# COMPUTE_CLUSTER0_DMSC_BOOT register map
Vendor: Texas Instruments
Peripheral module from a debugger description file (folder J7VCL).
Registers are 32-bit, access per field, reset 0x0 unless marked. A register's access mark holds for its fields unless they carry their own. Offsets are as the file gives them; lines under a group give offsets from that group; [hi:lo] are bit positions; {n}, {i} and the like mark numbered series; 'fields as' and 'values as' point back to an identical list; <NAME> marks a mode.

## COMPUTE_CLUSTER0_DMSC_BOOT
0x00 CC_REVISION ro reset 0x60000000 — Compute Cluster Revision Register
  [31:0] REV — TI internal data.
0x04 CC_MSMC_DEF ro — MSMC Definition Register
  [7:0] NUM_COREPAC — Denotes the number of corepacs connected to compute cluster.0h - Two corepacs
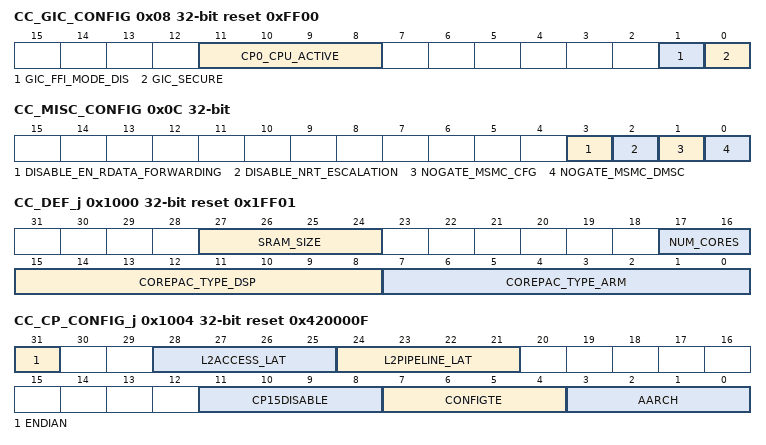
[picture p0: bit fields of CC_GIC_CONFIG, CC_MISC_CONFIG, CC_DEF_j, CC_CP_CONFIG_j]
0x08 CC_GIC_CONFIG reset 0xFF00 — GIC Configuration Register. GIC0 has input signals cpu_active_X_N (where X = A72SS number; N = Core number) which indicate when a core is active and available for routing SPIs unlike being in a software-transparent low-power mode in which case SPIs are not routed to, and a core wake-up would result in increased power consumption.
  [11:8] CP0_CPU_ACTIVE rw — A72SS0 Cores activeBits [11-10]: ReservedBit [9]:0h - A72SS0 Core 1 is in software-transparent low-power mode such as retention1h - A72SS0 Core 1 is active and available for shared SPIsBit [8]:0h - A72SS0 Core 0 is in software-transparent low-power mode such as retention1h - A72SS0 Core 0 is active and available for shared SPIs
  [1] GIC_FFI_MODE_DIS rw — Disables AXI auto responses to ARM in FFI mode.
  [0] GIC_SECURE rw — Not used on this SoC
0x0C CC_MISC_CONFIG — MISC Configuration Register.
  [3] DISABLE_EN_RDATA_FORWARDING rw — Disable control for AXI2VBUSMC return data forwarding feature
  [2] DISABLE_NRT_ESCALATION rw — Disable control for MSMC NRT escalation feature
  [1] NOGATE_MSMC_CFG rw — No gate control for the Configuration Interconnect (see
  [0] NOGATE_MSMC_DMSC rw — No gate control for the DMSC Interconnect (see
0x1000 CC_DEF_j ro reset 0x1FF01 — Compute Cluster Definition Register for MSMC port j Offset = 1000h*(j + 1); where j = 0h
  [27:24] SRAM_SIZE — SRAM size (if present in the corepac)0h - 0 bytes
  [17:16] NUM_CORES — Number of cores in the corepac0h - One core1h - Two cores2h - Four cores3h - Reserved
  [15:8] COREPAC_TYPE_DSP — Not used on this SoC
  [7:0] COREPAC_TYPE_ARM — MSMC port 'j' configuration0h - A53 corepac connected to MSMC port 'j'1h - A72 corepac connected to MSMC port 'j'2h to FEh - ReservedFFh - Port not used for ARM
0x1004 CC_CP_CONFIG_j reset 0x420000F — Compute Cluster Configuration Register for MSMC port j Offset = 1004h*(j + 1); where j = 0h
  [31] ENDIAN rw — Not used on this SoC
  [28:25] L2ACCESS_LAT rw — Not used on this SoC
  [24:21] L2PIPELINE_LAT rw — Not used on this SoC
  [11:8] CP15DISABLE rw — Disable write access to some secure CP15 registers. Valid only for Arm corepacs.
  [7:4] CONFIGTE rw — Enable T32 exceptions. It sets the initial value of the TE bit in the CP15 SCTLR register. This pin is sampled only during reset of the processor. Valid only for Arm corepacs.Bits [7-6]: ReservedBit [5]:0h - TE bit is LOW for core 1 of A72SS01h - TE bit is HIGH for core 1 of A72SS0Bit [4]:0h - TE bit is LOW for core 0 of A72SS01h - TE bit is HIGH for core 0 of A72SS0
  [3:0] AARCH rw — Arm Architecture. Valid only for Arm corepacs.Bits [3-2]: ReservedBit [1]:0h - AArch32 for core 1 of A72SS01h - AArch64 for core 1 of A72SS0Bit [0]:0h - AArch32 for core 0 of A72SS01h - AArch64 for core 0 of A72SS0
0x1008 CC_RST_VEC_LO_CP0_j rw — Core 0 Boot Vector Register (Low) for MSMC port j Offset = 1008h*(j + 1); where j = 0h
  [31:0] RESET_BASE_VECTOR_LO — Low reset base vector (bits [33-2]) for Core 0 of a corepac connected to MSMC port j.
0x100C CC_RST_VEC_HI_CP0_j — Core 0 Boot Vector Register (High) for MSMC port j Offset = 100Ch*(j + 1); where j = 0h
  [16:0] RESET_BASE_VECTOR_HI rw — High reset base vector (bits [39-34]) for Core 0 of a corepac connected to MSMC port j.
0x1010 CC_RST_VEC_LO_CP1_j rw — Core 1 Boot Vector Register (Low) for MSMC port j. Offset = 1010h*(j + 1); where j = 0h
  [31:0] RESET_BASE_VECTOR_LO — Low reset base vector (bits [33-2]) for Core 1 of a corepac connected to MSMC port j.
0x1014 CC_RST_VEC_HI_CP1_j — Core 1 Boot Vector Register (High) for MSMC port j. Offset = 1014h*(j + 1); where j = 0h
  [16:0] RESET_BASE_VECTOR_HI rw — High reset base vector (bits [39-34]) for Core 1 of a corepac connected to MSMC port j.
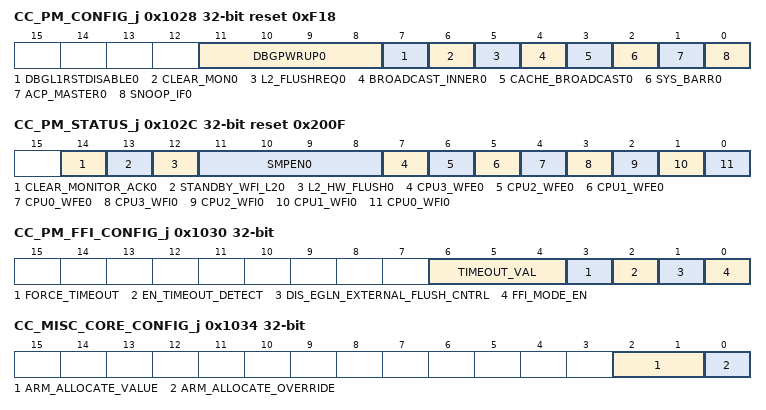
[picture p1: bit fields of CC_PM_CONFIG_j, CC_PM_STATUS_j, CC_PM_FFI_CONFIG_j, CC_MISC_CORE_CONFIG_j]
0x1028 CC_PM_CONFIG_j reset 0xF18 — Power Management Configuration Register for MSMC port j. Offset = 1028h*(j + 1); where j = 0h
  [11:8] DBGPWRUP0 rw — Core power upBits [11-10]: ReservedBit [9]:0h - A72SSj Core 1 is powered down1h - A72SSj Core 1 is powered upBit [8]:0h - A72SSj Core 0 is powered down1h - A72SSj Core 0 is powered up
  [7] DBGL1RSTDISABLE0 rw — Disable L1 data cache automatic invalidate on reset. This pin is sampled only during reset of the processor.0h - Enable automatic invalidation of L1 data cache on reset1h - Disable automatic invalidation of L1 data cache on reset
  [6] CLEAR_MON0 rw — Request to clear the external global exclusive monitor. This sends a WFE wake-up event to all cores in the cluster. When set HIGH the global exclusive monitor in the system is requesting the processor EVENT registers to be set HIGH.
  [5] L2_FLUSHREQ0 rw — ARM L2 hardware flush request
  [4] BROADCAST_INNER0 rw — Enable broadcasting of inner shareable and outer sharable transactions0h - Broadcasting disabled1h - Broadcasting enabled
  [3] CACHE_BROADCAST0 rw — Enable Broadcasting of cache maintenance transactions0h - Broadcasting disabled1h - Broadcasting enabled
  [2] SYS_BARR0 rw — Disable broadcasting of barriers0h - Broadcasting enabled1h - Broadcasting disabled
  [1] ACP_MASTER0 rw — ACP master is inactive and is not participating in coherency0h - ACP Master is active1h - ACP Master is inactiveNOTE: There must be no outstanding transactions when the master asserts this signal, and while it is asserted the master must not send any new transactions
  [0] SNOOP_IF0 rw — Snoop interface is inactive and not participating in coherency0h - Snoop interface is active1h - Snoop interface is inactive
0x102C CC_PM_STATUS_j ro reset 0x200F — Power Management Status Register for MSMC port j. Offset = 102Ch*(j + 1); where j = 0h
  [14] CLEAR_MONITOR_ACK0 — Clearing of the external global exclusive monitor acknowledge. When set HIGH the processor EVENT registers have been set HIGH.
  [13] STANDBY_WFI_L20 — L2 in WFI low power state indication
  [12] L2_HW_FLUSH0 — L2 hardware flush complete
  [11:8] SMPEN0 — Corepac taking part in coherency indication
  [7] CPU3_WFE0 — Reserved
  [6] CPU2_WFE0 — Reserved
  [5] CPU1_WFE0 — CPU in WFE state
  [4] CPU0_WFE0 — CPU in WFE state
  [3] CPU3_WFI0 — Reserved
  [2] CPU2_WFI0 — Reserved
  [1] CPU1_WFI0 — CPU in WFI state
  [0] CPU0_WFI0 — CPU in WFI state
0x1030 CC_PM_FFI_CONFIG_j — Power Management FFI Configuration Register for MSMC port j. Offset = 1030h*(j + 1); where j = 0h
  [6:4] TIMEOUT_VAL rw — Selects one of the 8 timeout values in number of cycles.0h - 10241h - 40962h - 163843h - 655364h - 2621445h - 10485766h - 20971527h - 4194303
  [3] FORCE_TIMEOUT rw — Forces timeout interrupt.
  [2] EN_TIMEOUT_DETECT rw — Enables timeout detect for snoop commands in AXI2VBUSMC.
  [1] DIS_EGLN_EXTERNAL_FLUSH_CNTRL rw — Disables AXI2VBUSMC external port control to trigger FFI mode.
  [0] FFI_MODE_EN rw — Enables FFI mode.
0x1034 CC_MISC_CORE_CONFIG_j — MISC Core Configuration Register for MSMC port j. Offset = 1034h*(j + 1); where j = 0h
  [2:1] ARM_ALLOCATE_VALUE rw — Override value for allocation hint.
  [0] ARM_ALLOCATE_OVERRIDE rw — Control to override arm outer allocation hint.
